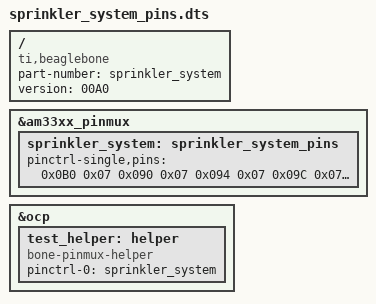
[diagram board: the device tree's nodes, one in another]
/dts-v1/;
/plugin/;

/ {
    compatible = "ti,beaglebone", "ti,beaglebone-black";

    /* identification */
    part-number = "sprinkler_system";
    version = "00A0";

    fragment@0 {
        target = <&am33xx_pinmux>;
        __overlay__ {
            sprinkler_system: sprinkler_system_pins {
                pinctrl-single,pins = <
		   /*Pins 8_3-18 Fast Slew Output Pullup MODE7		GPIO*/
		   0x0B0 0x07
//                 0x018 0x07
//		   0x01C 0x07
//		   0x008 0x07
//		   0x00C 0x07
		   0x090 0x07
		   0x094 0x07
		   0x09C 0x07
		   0x098 0x07
		   0x034 0x07
		   0x030 0x07
		   0x024 0x07
		   0x028 0x07
		   0x03C 0x07
		   0x038 0x07
		   0x02C 0x07
		   0x08C 0x07
                >;
            };
        };
    };

    fragment@1 {
        target = <&ocp>;
        __overlay__ {
            test_helper: helper {
   s             compatible = "bone-pinmux-helper";
                pinctrl-names = "default";
                pinctrl-0 = <&sprinkler_system>;
                status = "okay";
            };
        };
    };
};
